# Q32M210 register map
File version: 1.0
Registers are 32-bit, read-write, no defined reset value unless marked. A register's access mark holds for its fields unless they carry their own. Offsets are from the block's base; [hi:lo] are bit positions; {n}, {i} and the like mark numbered series; 'fields as' and 'values as' point back to an identical list.

## Clock_Configuration
Base 0x40000E00
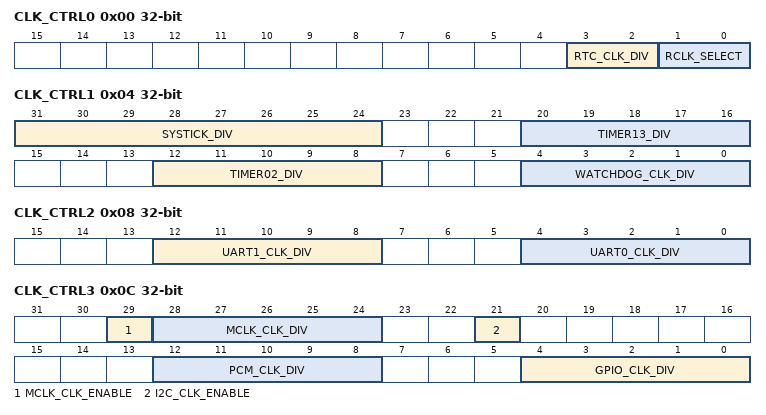
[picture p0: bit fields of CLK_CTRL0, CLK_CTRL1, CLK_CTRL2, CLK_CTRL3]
0x00 CLK_CTRL0 — Clock control register 0
  [3:2] RTC_CLK_DIV — Select the frequency for the real-time clock
    0=RTC_CLK_SELECT_2HZ (The real-time clock operates at 2 Hz); 1=RTC_CLK_SELECT_4HZ (The real-time clock operates at 4 Hz); 2=RTC_CLK_SELECT_8HZ (The real-time clock operates at 8 Hz); 3=RTC_CLK_SELECT_16HZ (The real-time clock operates at 16 Hz)
  [1:0] RCLK_SELECT — Select the source for the system root clock
    0=RCLK_SELECT_RC_OSC (The internal RC oscillator is used as the source for root clock); 2=RCLK_SELECT_RTC_XTAL (The RTC crystal is used as the source for root clock); 3=RCLK_SELECT_EXT (An external clock source is used as the source for root clock)
0x04 CLK_CTRL1 — Clock control register 1
  [31:24] SYSTICK_DIV — Select a divisor between 1 and 255 for the SYSTICK timer. The timer is disabled if 0xFF is written to this field.
    255=SYSTICK_DISABLE (Disable the SYSTICK timer); 0=Divide the root clock by 2; 1=Divide the root clock by 4; 2=Divide the root clock by 6; 3=Divide the root clock by 8; 4=Divide the root clock by 10; 5=Divide the root clock by 12; 6=Divide the root clock by 14; 7=Divide the root clock by 16; 15=Divide the root clock by 32; 31=Divide the root clock by 64
  [20:16] TIMER13_DIV — Select a divisor between 1 and 32 for timers 1 and 3
    {v}=Divide the root clock by {v+1} (v=0..7); 15=Divide the root clock by 16; 31=Divide the root clock by 32
  [12:8] TIMER02_DIV — Select a divisor between 1 and 32 for timers 0 and 2
    values as TIMER13_DIV
  [4:0] WATCHDOG_CLK_DIV — Select a divisor between 1 and 32 for the watchdog clock
    values as TIMER13_DIV
0x08 CLK_CTRL2 — Clock control register 2
  [12:8] UART1_CLK_DIV — Select a divisor between 1 and 32 for the clock for UART1
    values as CLK_CTRL1.TIMER13_DIV
  [4:0] UART0_CLK_DIV — Select a divisor between 1 and 32 for the clock for UART0
    values as CLK_CTRL1.TIMER13_DIV
0x0C CLK_CTRL3 — Clock control register 3
  [29] MCLK_CLK_ENABLE — Enable the MCLK clock to the analog components
    0=MCLK_CLK_DISABLE (Disable MCLK clock output); 1=MCLK_CLK_ENABLE (Enable MCLK clock output)
  [28:24] MCLK_CLK_DIV — Select a divisor between 1 and 32 for MCLK
    0=Divide the root clock by 2; 1=Divide the root clock by 4; 2=Divide the root clock by 6; 3=Divide the root clock by 8; 4=Divide the root clock by 10; 5=Divide the root clock by 12; 6=Divide the root clock by 14; 7=Divide the root clock by 16; 15=Divide the root clock by 32; 31=Divide the root clock by 64
  [21] I2C_CLK_ENABLE — Enable the I2C clock input to the I2C interface
    0=I2C_CLK_DISABLE (Disable I2C clock output); 1=I2C_CLK_ENABLE (Enable I2C clock output)
  [12:8] PCM_CLK_DIV — Select a divisor between 1 and 32 for the clock for PCM
    values as CLK_CTRL1.TIMER13_DIV
  [4:0] GPIO_CLK_DIV — Select a divisor between 1 and 32 for the clock for GPIO input sampling
    values as CLK_CTRL1.TIMER13_DIV
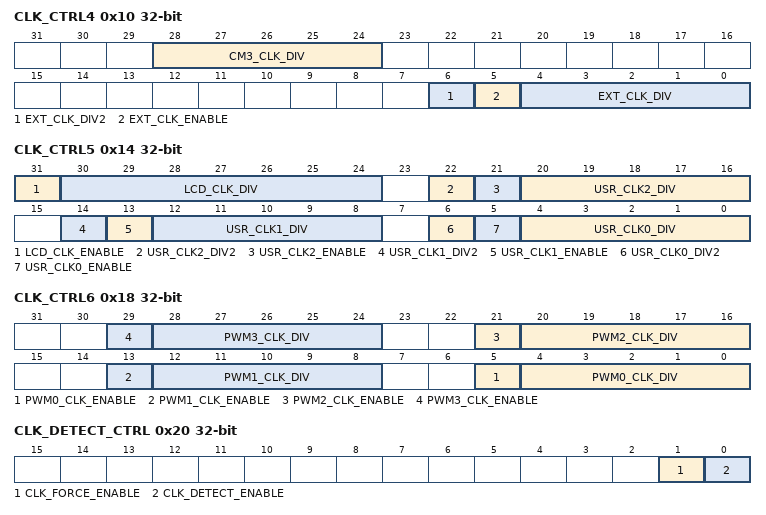
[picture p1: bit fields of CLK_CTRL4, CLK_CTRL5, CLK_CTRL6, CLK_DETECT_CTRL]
0x10 CLK_CTRL4 — Clock control register 4
  [28:24] CM3_CLK_DIV — Select a divisor between 1 and 32 for the clock for the ARM Cortex-M3 core
    values as CLK_CTRL1.TIMER13_DIV
  [6] EXT_CLK_DIV2 — Divide EXT_CLK by 2 (ensures 50% duty cycle)
    0=EXT_CLK_DIV2_DISABLE (Do not further divide the EXT_CLK output by 2); 1=EXT_CLK_DIV2_ENABLE (Divide the EXT_CLK output by 2)
  [5] EXT_CLK_ENABLE — Enable the external clock for output
    0=EXT_CLK_DISABLE (Disable external clock output); 1=EXT_CLK_ENABLE (Enable external clock output)
  [4:0] EXT_CLK_DIV — Select a divisor between 1 and 32 for the external clock output
    values as CLK_CTRL1.TIMER13_DIV
0x14 CLK_CTRL5 — Clock control register 5
  [31] LCD_CLK_ENABLE — Enable LCD_CLK
    0=LCD_CLK_DISABLE (Disable LCD clock output); 1=LCD_CLK_ENABLE (Enable LCD clock output)
  [30:24] LCD_CLK_DIV — Select a divisor between 1 and 128 for LCD_CLK. LCD_CLK = MCLK / (1024 * (LCD_CLK_DIV + 1))
    {v}=Divide MCLK by 1024 + {v+1} (v=0..7); 15=Divide MCLK by 1024 + 16; 31=Divide MCLK by 1024 + 32; 63=Divide MCLK by 1024 + 64; 127=Divide MCLK by 1024 + 128
  [22] USR_CLK2_DIV2 — Divide user clock 2 by 2 (ensures 50% duty cycle)
    0=USR_CLK2_DIV2_DISABLE (Do not further divide user clock 2 output by 2); 1=USR_CLK2_DIV2_ENABLE (Divide user clock 2 output by 2)
  [21] USR_CLK2_ENABLE — Enable user clock 2 for output
    0=USR_CLK2_DISABLE (Disable user clock 2 output); 1=USR_CLK2_ENABLE (Enable user clock 2 output)
  [20:16] USR_CLK2_DIV — Select a divisor between 1 and 32 for user clock 2
    values as CLK_CTRL1.TIMER13_DIV
  [14] USR_CLK1_DIV2 — Divide user clock 1 by 2 (ensures 50% duty cycle)
    0=USR_CLK1_DIV2_DISABLE (Do not further divide user clock 1 output by 2); 1=USR_CLK1_DIV2_ENABLE (Divide user clock 1 output by 2)
  [13] USR_CLK1_ENABLE — Enable user clock 1 output
    0=USR_CLK1_DISABLE (Disable user clock 1 output); 1=USR_CLK1_ENABLE (Enable user clock 1 output)
  [12:8] USR_CLK1_DIV — Select a divisor between 1 and 32 for user clock 1
    values as CLK_CTRL1.TIMER13_DIV
  [6] USR_CLK0_DIV2 — Divide user clock 0 by 2 (ensures 50% duty cycle)
    0=USR_CLK0_DIV2_DISABLE (Do not further divide user clock 0 output by 2); 1=USR_CLK0_DIV2_ENABLE (Divide user clock 0 output by 2)
  [5] USR_CLK0_ENABLE — Enable user clock 0 output
    0=USR_CLK0_DISABLE (Disable user clock 0 output); 1=USR_CLK0_ENABLE (Enable user clock 0 output)
  [4:0] USR_CLK0_DIV — Select a divisor between 1 and 32 for user clock 0
    values as CLK_CTRL1.TIMER13_DIV
0x18 CLK_CTRL6 — Clock control register 6
  [8n+5] PWM{n}_CLK_ENABLE (n=0..3) — Enable the PWM{n} clock
    0=PWM{n}_CLK_DISABLE (Disable PWM{n} clock output); 1=PWM{n}_CLK_ENABLE (Enable PWM{n} clock output)
  [8n+4:8n] PWM{n}_CLK_DIV (n=0..3) — Select a divisor between 1 and 32 for PWM{n}_CLK. PWM{n}_CLK = MCLK / (PWM{n}_CLK_DIV + 1)
    {v}=Divide MCLK by 1024 + {v+1} (v=0..7); 15=Divide MCLK by 1024 + 16; 31=Divide MCLK by 1024 + 32
0x1C CLK_CTRL7 — Clock control register 7
  [4:0] CP_CLK_DIV — Select a divisor between 1 and 32 for the charge pump clock. CP_CLK = MCLK / (2 * CP_CLK_DIV)
    0=Divide MCLK by 2; 1=Divide MCLK by 4; 2=Divide MCLK by 6; 3=Divide MCLK by 8; 4=Divide MCLK by 10; 5=Divide MCLK by 12; 6=Divide MCLK by 14; 7=Divide MCLK by 16; 9=Divide MCLK by 20; 11=Divide MCLK by 24; 13=Divide MCLK by 28; 15=Divide MCLK by 32; 31=Divide MCLK by 64
0x20 CLK_DETECT_CTRL — External Clock Detection Control and Configuration
  [1] CLK_FORCE_ENABLE — Select whether the external clock is forced to RC_CLK when no clock is detected
    0=CLK_DETECT_FORCE_DISABLE (The root clock is not forced to RC clock if no external clock is detected); 1=CLK_DETECT_FORCE_ENABLE (The root clock is forced to RC clock if no external clock is detected)
  [0] CLK_DETECT_ENABLE — Select whether the system attempts to detect an external clock
    0=CLK_DETECT_DISABLE (Do not attempt to detect an external clock input); 1=CLK_DETECT_ENABLE (Attempt to detect an external clock input)
0x24 CLK_DETECT_STATUS — External Clock Detection Status
  [0] EXT_CLK_STATUS — Indicates whether an external clock has been present since this bit was last cleared
    0=EXT_CLK_DETECTED (An external clock input has been detected as present); 1=EXT_CLK_NOT_DETECTED (No external clock input has been detected); 1=EXT_CLK_DETECT_CLEAR (Clear the external clock detection status)
